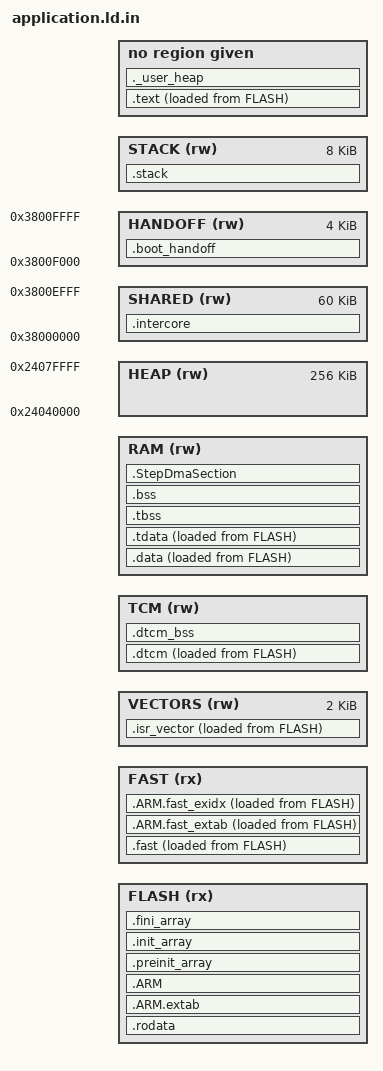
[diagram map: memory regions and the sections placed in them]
/* Runtime-owned sections include compiler TLS and a bounded C/C++ heap.
 * Each image has private RAM; SRAM4 is reserved for the shared inter-core byte queues. */
ENTRY(Reset_Handler)
MEMORY
{
    FLASH (rx) : ORIGIN = @GIGA_FLASH_ORIGIN@, LENGTH = @GIGA_FLASH_LENGTH@
    @GIGA_CODE_MEMORY@
    FAST (rx) : ORIGIN = @GIGA_FAST_ORIGIN@, LENGTH = @GIGA_FAST_LENGTH@
    VECTORS (rw) : ORIGIN = @GIGA_VECTOR_ORIGIN@, LENGTH = 2K
    TCM (rw) : ORIGIN = @GIGA_TCM_ORIGIN@, LENGTH = @GIGA_TCM_LENGTH@
    RAM (rw) : ORIGIN = @GIGA_RAM_ORIGIN@, LENGTH = @GIGA_RAM_LENGTH@
    HEAP (rw) : ORIGIN = 0x24040000, LENGTH = 256K
    SHARED (rw) : ORIGIN = 0x38000000, LENGTH = 60K
    HANDOFF (rw) : ORIGIN = 0x3800F000, LENGTH = 4K
    STACK (rw) : ORIGIN = @GIGA_STACK_ORIGIN@, LENGTH = 8K
    @GIGA_GUI_MEMORY@
}
@GIGA_CODE_ALIAS@
_Min_Heap_Size = 16K;
_Min_Stack_Size = LENGTH(STACK);
_estack = ORIGIN(STACK) + LENGTH(STACK);
_sstack = ORIGIN(STACK);
SECTIONS
{
  @GIGA_GUI_SECTIONS@
  /* The startup code goes first into FLASH */
  .isr_vector :
  {
    . = ALIGN(4);
    KEEP(*(.isr_vector)) /* Startup code */
    . = ALIGN(4);
  } >VECTORS AT>FLASH

  /* RAM-resident interrupt and motion fast paths; the image packer emits
     explicit load/zero records. Constants travel with their owning object. */
  .fast : ALIGN(4)
  {
    __fast_start = .;
    *(.fast .fast.* .itcm .itcm.* .RamFunc .RamFunc.*)
    @GIGA_FAST_OBJECTS@
    __fast_end = .;
    . = ALIGN(4);
  } >FAST AT>FLASH
  .ARM.fast_extab : ALIGN(4) { @GIGA_FAST_EXTAB@ } >FAST AT>FLASH
  .ARM.fast_exidx : ALIGN(4) {
    __fast_exidx_start = .;
    @GIGA_FAST_EXIDX@
    __fast_exidx_end = .;
  } >FAST AT>FLASH
  .dtcm : ALIGN(8) { *(.dtcm .dtcm.*) @GIGA_TCM_DATA@ . = ALIGN(8); } >TCM AT>FLASH
  .dtcm_bss (NOLOAD) : ALIGN(8) { *(.dtcm_bss .dtcm_bss.*) @GIGA_TCM_BSS@ . = ALIGN(8); } >TCM

  /* The program code and other data goes into FLASH */
  .text :
  {
    . = ALIGN(4);
    *(.text)           /* .text sections (code) */
    *(.text*)          /* .text* sections (code) */
    *(.glue_7)         /* glue arm to thumb code */
    *(.glue_7t)        /* glue thumb to arm code */
    *(.eh_frame)

    KEEP (*(.init))
    KEEP (*(.fini))

    . = ALIGN(4);
    _etext = .;        /* define a global symbols at end of code */
  } >CODE AT>FLASH

  /* Keep data reads out of FMC even in RAM-debug. ES0445 2.7.3 forbids
     unaligned FMC reads; prebuilt libc/C++ routines can make those accesses
     to strings and exception metadata. Only instructions move to SDRAM. */
  .rodata :
  {
    . = ALIGN(4);
    *(.rodata)         /* .rodata sections (constants, strings, etc.) */
    *(.rodata*)        /* .rodata* sections (constants, strings, etc.) */
    . = ALIGN(4);
  } >FLASH

  .ARM.extab (READONLY) : /* The "READONLY" keyword is only supported in GCC11 and later, remove it if using GCC10 or earlier. */
  {
    . = ALIGN(4);
    *(.ARM.extab* .gnu.linkonce.armextab.*)
    . = ALIGN(4);
  } >FLASH

  .ARM (READONLY) : /* The "READONLY" keyword is only supported in GCC11 and later, remove it if using GCC10 or earlier. */
  {
    . = ALIGN(4);
    __exidx_start = .;
    *(.ARM.exidx*)
    __exidx_end = .;
    . = ALIGN(4);
  } >FLASH

  .preinit_array (READONLY) : /* The "READONLY" keyword is only supported in GCC11 and later, remove it if using GCC10 or earlier. */
  {
    . = ALIGN(4);
    PROVIDE_HIDDEN (__preinit_array_start = .);
    KEEP (*(.preinit_array*))
    PROVIDE_HIDDEN (__preinit_array_end = .);
    . = ALIGN(4);
  } >FLASH

  .init_array (READONLY) : /* The "READONLY" keyword is only supported in GCC11 and later, remove it if using GCC10 or earlier. */
  {
    . = ALIGN(4);
    PROVIDE_HIDDEN (__init_array_start = .);
    KEEP (*(SORT(.init_array.*)))
    KEEP (*(.init_array*))
    PROVIDE_HIDDEN (__init_array_end = .);
    . = ALIGN(4);
  } >FLASH

  .fini_array (READONLY) : /* The "READONLY" keyword is only supported in GCC11 and later, remove it if using GCC10 or earlier. */
  {
    . = ALIGN(4);
    PROVIDE_HIDDEN (__fini_array_start = .);
    KEEP (*(SORT(.fini_array.*)))
    KEEP (*(.fini_array*))
    PROVIDE_HIDDEN (__fini_array_end = .);
    . = ALIGN(4);
  } >FLASH

  /* used by the startup to initialize data */
  _sidata = LOADADDR(.data);

  /* General initialized data belongs in bus-accessible private RAM. */
  .data :
  {
    . = ALIGN(4);
    _sdata = .;        /* create a global symbol at data start */
    *(.data)           /* .data sections */
    *(.data*)          /* .data* sections */
    *(.RamFunc)        /* .RamFunc sections */
    *(.RamFunc*)       /* .RamFunc* sections */

    . = ALIGN(4);
  } >RAM AT>FLASH

 /* Initialized TLS data section */
  .tdata : ALIGN(4)
  {
    *(.tdata .tdata.* .gnu.linkonce.td.*)
    . = ALIGN(4);
    _edata = .;        /* define a global symbol at data end */
    PROVIDE(__data_end = .);
    PROVIDE(__tdata_end = .);
  } >RAM AT>FLASH

  PROVIDE( __tdata_start = ADDR(.tdata) );
  PROVIDE( __tdata_size = __tdata_end - __tdata_start );

  PROVIDE( __data_start = ADDR(.data) );
  PROVIDE( __data_size = __data_end - __data_start );

  PROVIDE( __tdata_source = LOADADDR(.tdata) );
  PROVIDE( __tdata_source_end = LOADADDR(.tdata) + SIZEOF(.tdata) );
  PROVIDE( __tdata_source_size = __tdata_source_end - __tdata_source );

  PROVIDE( __data_source = LOADADDR(.data) );
  PROVIDE( __data_source_end = __tdata_source_end );
  PROVIDE( __data_source_size = __data_source_end - __data_source );
  /* Uninitialized data section */
  .tbss (NOLOAD) : ALIGN(4)
  {
     /* This is used by the startup in order to initialize the .bss secion */
    _sbss = .;         /* define a global symbol at bss start */
    __bss_start__ = _sbss;
    *(.tbss .tbss.*)
    . = ALIGN(4);
    PROVIDE( __tbss_end = . );
  } >RAM

  PROVIDE( __tbss_start = ADDR(.tbss) );
  PROVIDE( __tbss_size = __tbss_end - __tbss_start );
  PROVIDE( __tbss_offset = ADDR(.tbss) - ADDR(.tdata) );

  PROVIDE( __tls_base = __tdata_start );
  PROVIDE( __tls_end = __tbss_end );
  PROVIDE( __tls_size = __tls_end - __tls_base );
  PROVIDE( __tls_align = MAX(ALIGNOF(.tdata), ALIGNOF(.tbss)) );
  PROVIDE( __tls_size_align = (__tls_size + __tls_align - 1) & ~(__tls_align - 1) );
  PROVIDE( __arm32_tls_tcb_offset = MAX(8, __tls_align) );
  PROVIDE( __arm64_tls_tcb_offset = MAX(16, __tls_align) );

  .bss (NOLOAD) : ALIGN(4)
  {
    *(.bss)
    *(.bss*)
    *(COMMON)

      . = ALIGN(4);
    _ebss = .;         /* define a global symbol at bss end */
    __bss_end__ = _ebss;
      PROVIDE( __bss_end = .);
  } >RAM
  PROVIDE( __non_tls_bss_start = ADDR(.bss) );

  PROVIDE( __bss_start = __tbss_start );
  PROVIDE( __bss_size = __bss_end - __bss_start );

  .StepDmaSection (NOLOAD) :
  {
    . = ALIGN(32);
    *(.StepDmaSection)
    . = ALIGN(32);
  } >RAM

  /* Reserve the minimum heap in private RAM. The application-owned _sbrk()
   * may grow from __HeapBase up to __HeapLimit. */
  ._user_heap (NOLOAD) :
  {
    . = ALIGN(8);
    end = .;
    _end = .;
    __HeapBase = .;
    . = . + _Min_Heap_Size;
    . = ALIGN(8);
    __HeapReservedEnd = .;
    __HeapLimit = ORIGIN(@GIGA_HEAP_REGION@) + LENGTH(@GIGA_HEAP_REGION@);
  } >@GIGA_HEAP_REGION@

  .intercore (NOLOAD) : ALIGN(32)
  {
    KEEP(*(.intercore))
  } >SHARED

  .boot_handoff (NOLOAD) : { . = . + LENGTH(HANDOFF); } >HANDOFF

  /* The MSP is used as the ThreadX system/interrupt stack. */
  .stack (NOLOAD) :
  {
    . = ALIGN(8);
    __StackLimit = .;
    . = . + _Min_Stack_Size;
    . = ALIGN(8);
    __StackTop = .;
  } >STACK

  ASSERT(__HeapReservedEnd <= __HeapLimit,
         "Minimum heap does not fit in private RAM")
  ASSERT(__StackTop == _estack,
         "Main stack does not end at the top of the private stack region")
  ASSERT(SIZEOF(.isr_vector) <= LENGTH(VECTORS), "Vectors overflow")
  ASSERT(SIZEOF(.intercore) <= LENGTH(SHARED), "ICC overlaps boot handoff")
  ASSERT(SIZEOF(.fast) <= LENGTH(FAST), "Real-time code exceeds internal RAM")
  .ARM.attributes 0 : { *(.ARM.attributes) }
}
